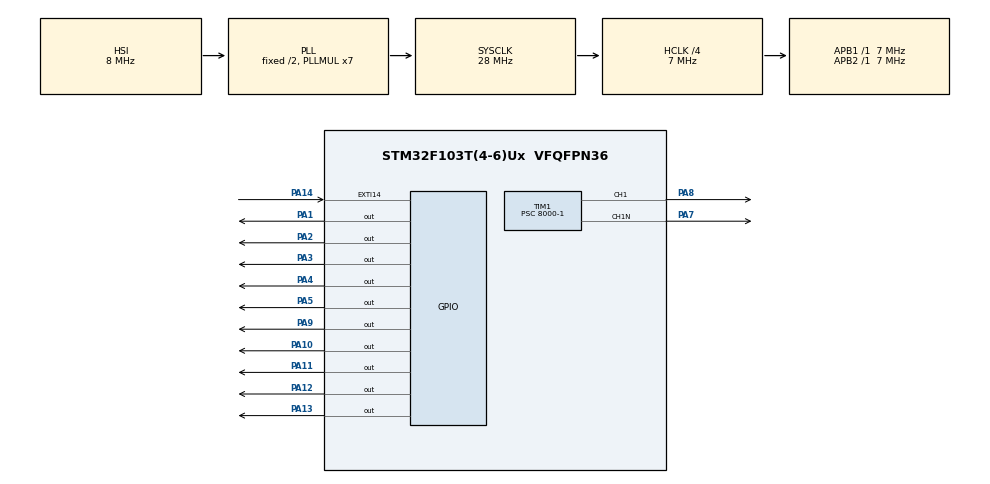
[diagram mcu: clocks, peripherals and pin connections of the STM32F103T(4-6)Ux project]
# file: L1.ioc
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Mcu.Family=STM32F1
Mcu.Name=STM32F103T(4-6)Ux
Mcu.Package=VFQFPN36
NVIC.EXTI15_10_IRQn=true\:0\:0\:false\:false\:true\:true\:true\:true
NVIC.PriorityGroup=NVIC_PRIORITYGROUP_4
NVIC.TIM1_BRK_IRQn=true\:0\:0\:false\:false\:true\:true\:true\:true
NVIC.TIM1_CC_IRQn=true\:0\:0\:false\:false\:true\:true\:true\:true
NVIC.TIM1_TRG_COM_IRQn=true\:0\:0\:false\:false\:true\:true\:true\:true
NVIC.TIM1_UP_IRQn=true\:0\:0\:false\:false\:true\:true\:true\:true
NVIC.TIM2_IRQn=true\:0\:0\:false\:false\:true\:true\:true\:true
PA1.PinState=GPIO_PIN_SET
PA1.Signal=GPIO_Output
PA10.Signal=GPIO_Output
PA11.Signal=GPIO_Output
PA12.Signal=GPIO_Output
PA13.Signal=GPIO_Output
PA14.Signal=GPXTI14
PA2.PinState=GPIO_PIN_SET
PA2.Signal=GPIO_Output
PA3.PinState=GPIO_PIN_SET
PA3.Signal=GPIO_Output
PA4.PinState=GPIO_PIN_SET
PA4.Signal=GPIO_Output
PA5.PinState=GPIO_PIN_SET
PA5.Signal=GPIO_Output
PA7.Mode=PWM Generation1 CH1 CH1N
PA7.Signal=TIM1_CH1N
PA8.Signal=S_TIM1_CH1
PA9.Signal=GPIO_Output
ProjectManager.HeapSize=0x200
ProjectManager.StackSize=0x400
ProjectManager.TargetToolchain=STM32CubeIDE
RCC.AHBCLKDivider=RCC_SYSCLK_DIV4
RCC.AHBFreq_Value=7000000
RCC.APB1Freq_Value=7000000
RCC.APB1TimFreq_Value=7000000
RCC.APB2Freq_Value=7000000
RCC.APB2TimFreq_Value=7000000
RCC.HCLKFreq_Value=7000000
RCC.PLLMUL=RCC_PLL_MUL7
RCC.SYSCLKFreq_VALUE=28000000
RCC.SYSCLKSource=RCC_SYSCLKSOURCE_PLLCLK
RCC.USBFreq_Value=28000000
SH.S_TIM1_CH1.0=TIM1_CH1,PWM Generation1 CH1 CH1N
TIM1.AutoReloadPreload=TIM_AUTORELOAD_PRELOAD_ENABLE
TIM1.Channel-PWM\ Generation1\ CH1\ CH1N=TIM_CHANNEL_1
TIM1.OCNPolarity_1=TIM_OCNPOLARITY_HIGH
TIM1.OCPolarity_1=TIM_OCPOLARITY_HIGH
TIM1.Period=2500-1
TIM1.Prescaler=8000-1
TIM1.Pulse-PWM\ Generation1\ CH1\ CH1N=1250-1
TIM2.Period=1250-1
TIM2.Prescaler=8000-1
VP_SYS_VS_ND.Mode=No_Debug
VP_TIM1_VS_ClockSourceINT.Mode=Internal
VP_TIM2_VS_ClockSourceINT.Mode=Internal
board=custom

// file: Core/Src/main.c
/* USER CODE BEGIN Header */
/**
  ******************************************************************************
  * @file           : main.c
  * @brief          : Main program body
  ******************************************************************************
  * @attention
  *
  * Copyright (c) 2024 STMicroelectronics.
  * All rights reserved.
  *
  * This software is licensed under terms that can be found in the LICENSE file
  * in the root directory of this software component.
  * If no LICENSE file comes with this software, it is provided AS-IS.
  *
  ******************************************************************************
  */
/* USER CODE END Header */
#include "main.h"

TIM_HandleTypeDef htim1;
TIM_HandleTypeDef htim2;

void SystemClock_Config(void);
static void MX_GPIO_Init(void);
static void MX_TIM2_Init(void);
static void MX_TIM1_Init(void);

int main(void)
{

  /* MCU Configuration--------------------------------------------------------*/

  /* Reset of all peripherals, Initializes the Flash interface and the Systick. */
  HAL_Init();

  /* Configure the system clock */
  SystemClock_Config();

  /* Initialize all configured peripherals */
  MX_GPIO_Init();
  MX_TIM2_Init();
  MX_TIM1_Init();
  /* USER CODE BEGIN 2 */
  HAL_TIM_Base_Start_IT(&htim2); /* turn on timer with IT-interaps*/ // task2
  HAL_TIM_PWM_Start_IT(&htim1, TIM_CHANNEL_1); // task3
  HAL_TIMEx_PWMN_Start_IT(&htim1, TIM_CHANNEL_1); // task3
  /* USER CODE END 2 */

  /* Infinite loop */
  /* USER CODE BEGIN WHILE */
  while (1)
  {
	// HAL_GPIO_WritePin(GPIOA, GPIO_PIN_0, HAL_GPIO_ReadPin(GPIOA, GPIO_PIN_4)); // write value from PinA4 to PinA0
    /* USER CODE END WHILE */

  }
}

void SystemClock_Config(void)
{
  RCC_OscInitTypeDef RCC_OscInitStruct = {0};
  RCC_ClkInitTypeDef RCC_ClkInitStruct = {0};

  /** Initializes the RCC Oscillators according to the specified parameters
  * in the RCC_OscInitTypeDef structure.
  */
  RCC_OscInitStruct.OscillatorType = RCC_OSCILLATORTYPE_HSI;
  RCC_OscInitStruct.HSIState = RCC_HSI_ON;
  RCC_OscInitStruct.HSICalibrationValue = RCC_HSICALIBRATION_DEFAULT;
  RCC_OscInitStruct.PLL.PLLState = RCC_PLL_ON;
  RCC_OscInitStruct.PLL.PLLSource = RCC_PLLSOURCE_HSI_DIV2;
  RCC_OscInitStruct.PLL.PLLMUL = RCC_PLL_MUL7;
  if (HAL_RCC_OscConfig(&RCC_OscInitStruct) != HAL_OK)
  {
    Error_Handler();
  }

  /** Initializes the CPU, AHB and APB buses clocks
  */
  RCC_ClkInitStruct.ClockType = RCC_CLOCKTYPE_HCLK|RCC_CLOCKTYPE_SYSCLK
                              |RCC_CLOCKTYPE_PCLK1|RCC_CLOCKTYPE_PCLK2;
  RCC_ClkInitStruct.SYSCLKSource = RCC_SYSCLKSOURCE_PLLCLK;
  RCC_ClkInitStruct.AHBCLKDivider = RCC_SYSCLK_DIV4;
  RCC_ClkInitStruct.APB1CLKDivider = RCC_HCLK_DIV1;
  RCC_ClkInitStruct.APB2CLKDivider = RCC_HCLK_DIV1;

  if (HAL_RCC_ClockConfig(&RCC_ClkInitStruct, FLASH_LATENCY_1) != HAL_OK)
  {
    Error_Handler();
  }
}

static void MX_TIM1_Init(void)
{

  TIM_ClockConfigTypeDef sClockSourceConfig = {0};
  TIM_MasterConfigTypeDef sMasterConfig = {0};
  TIM_OC_InitTypeDef sConfigOC = {0};
  TIM_BreakDeadTimeConfigTypeDef sBreakDeadTimeConfig = {0};

  htim1.Instance = TIM1;
  htim1.Init.Prescaler = 8000-1;
  htim1.Init.CounterMode = TIM_COUNTERMODE_UP;
  htim1.Init.Period = 2500-1;
  htim1.Init.ClockDivision = TIM_CLOCKDIVISION_DIV1;
  htim1.Init.RepetitionCounter = 0;
  htim1.Init.AutoReloadPreload = TIM_AUTORELOAD_PRELOAD_ENABLE;
  if (HAL_TIM_Base_Init(&htim1) != HAL_OK)
  {
    Error_Handler();
  }
  sClockSourceConfig.ClockSource = TIM_CLOCKSOURCE_INTERNAL;
  if (HAL_TIM_ConfigClockSource(&htim1, &sClockSourceConfig) != HAL_OK)
  {
    Error_Handler();
  }
  if (HAL_TIM_PWM_Init(&htim1) != HAL_OK)
  {
    Error_Handler();
  }
  sMasterConfig.MasterOutputTrigger = TIM_TRGO_RESET;
  sMasterConfig.MasterSlaveMode = TIM_MASTERSLAVEMODE_DISABLE;
  if (HAL_TIMEx_MasterConfigSynchronization(&htim1, &sMasterConfig) != HAL_OK)
  {
    Error_Handler();
  }
  sConfigOC.OCMode = TIM_OCMODE_PWM1;
  sConfigOC.Pulse = 1250-1;
  sConfigOC.OCPolarity = TIM_OCPOLARITY_HIGH;
  sConfigOC.OCNPolarity = TIM_OCNPOLARITY_HIGH;
  sConfigOC.OCFastMode = TIM_OCFAST_DISABLE;
  sConfigOC.OCIdleState = TIM_OCIDLESTATE_RESET;
  sConfigOC.OCNIdleState = TIM_OCNIDLESTATE_RESET;
  if (HAL_TIM_PWM_ConfigChannel(&htim1, &sConfigOC, TIM_CHANNEL_1) != HAL_OK)
  {
    Error_Handler();
  }
  sBreakDeadTimeConfig.OffStateRunMode = TIM_OSSR_DISABLE;
  sBreakDeadTimeConfig.OffStateIDLEMode = TIM_OSSI_DISABLE;
  sBreakDeadTimeConfig.LockLevel = TIM_LOCKLEVEL_OFF;
  sBreakDeadTimeConfig.DeadTime = 0;
  sBreakDeadTimeConfig.BreakState = TIM_BREAK_DISABLE;
  sBreakDeadTimeConfig.BreakPolarity = TIM_BREAKPOLARITY_HIGH;
  sBreakDeadTimeConfig.AutomaticOutput = TIM_AUTOMATICOUTPUT_DISABLE;
  if (HAL_TIMEx_ConfigBreakDeadTime(&htim1, &sBreakDeadTimeConfig) != HAL_OK)
  {
    Error_Handler();
  }
  HAL_TIM_MspPostInit(&htim1);

}

static void MX_TIM2_Init(void)
{

  TIM_ClockConfigTypeDef sClockSourceConfig = {0};
  TIM_MasterConfigTypeDef sMasterConfig = {0};

  htim2.Instance = TIM2;
  htim2.Init.Prescaler = 8000-1;
  htim2.Init.CounterMode = TIM_COUNTERMODE_UP;
  htim2.Init.Period = 1250-1;
  htim2.Init.ClockDivision = TIM_CLOCKDIVISION_DIV1;
  htim2.Init.AutoReloadPreload = TIM_AUTORELOAD_PRELOAD_DISABLE;
  if (HAL_TIM_Base_Init(&htim2) != HAL_OK)
  {
    Error_Handler();
  }
  sClockSourceConfig.ClockSource = TIM_CLOCKSOURCE_INTERNAL;
  if (HAL_TIM_ConfigClockSource(&htim2, &sClockSourceConfig) != HAL_OK)
  {
    Error_Handler();
  }
  sMasterConfig.MasterOutputTrigger = TIM_TRGO_RESET;
  sMasterConfig.MasterSlaveMode = TIM_MASTERSLAVEMODE_DISABLE;
  if (HAL_TIMEx_MasterConfigSynchronization(&htim2, &sMasterConfig) != HAL_OK)
  {
    Error_Handler();
  }

}

static void MX_GPIO_Init(void)
{
  GPIO_InitTypeDef GPIO_InitStruct = {0};

  /* GPIO Ports Clock Enable */
  __HAL_RCC_GPIOA_CLK_ENABLE();

  /*Configure GPIO pin Output Level */
  HAL_GPIO_WritePin(GPIOA, GPIO_PIN_1|GPIO_PIN_2|GPIO_PIN_3|GPIO_PIN_4
                          |GPIO_PIN_5, GPIO_PIN_SET);

  /*Configure GPIO pin Output Level */
  HAL_GPIO_WritePin(GPIOA, GPIO_PIN_9|GPIO_PIN_10|GPIO_PIN_11|GPIO_PIN_12
                          |GPIO_PIN_13, GPIO_PIN_RESET);

  /*Configure GPIO pins : PA1 PA2 PA3 PA4
                           PA5 PA9 PA10 PA11
                           PA12 PA13 */
  GPIO_InitStruct.Pin = GPIO_PIN_1|GPIO_PIN_2|GPIO_PIN_3|GPIO_PIN_4
                          |GPIO_PIN_5|GPIO_PIN_9|GPIO_PIN_10|GPIO_PIN_11
                          |GPIO_PIN_12|GPIO_PIN_13;
  GPIO_InitStruct.Mode = GPIO_MODE_OUTPUT_PP;
  GPIO_InitStruct.Pull = GPIO_NOPULL;
  GPIO_InitStruct.Speed = GPIO_SPEED_FREQ_LOW;
  HAL_GPIO_Init(GPIOA, &GPIO_InitStruct);

  /*Configure GPIO pin : PA14 */
  GPIO_InitStruct.Pin = GPIO_PIN_14;
  GPIO_InitStruct.Mode = GPIO_MODE_IT_RISING;
  GPIO_InitStruct.Pull = GPIO_NOPULL;
  HAL_GPIO_Init(GPIOA, &GPIO_InitStruct);

  /* EXTI interrupt init*/
  HAL_NVIC_SetPriority(EXTI15_10_IRQn, 0, 0);
  HAL_NVIC_EnableIRQ(EXTI15_10_IRQn);

}

/* USER CODE BEGIN 4 */
void HAL_GPIO_EXTI_Callback(uint16_t GPIO_Pin)
{
	uint16_t pins[] = {GPIO_PIN_1, GPIO_PIN_2, GPIO_PIN_3, GPIO_PIN_4, GPIO_PIN_5, GPIO_PIN_9, GPIO_PIN_10, GPIO_PIN_11, GPIO_PIN_12, GPIO_PIN_13};
	int pin_count = sizeof(pins) / sizeof(pins[0]);

	for(int i = 0; i < pin_count; i++)
	{
		HAL_GPIO_TogglePin(GPIOA, pins[i]);
	}
}
/* USER CODE END 4 */

void Error_Handler(void)
{
  __disable_irq();
  while (1)
  {
  }
}
